# ARM_Example register map
Vendor: Infineon; Series: ARMCM3; File version: 1.2
CPU: CM3 r1p0, little endian, MPU, FPU, 3 interrupt priority bits
Registers are 32-bit, read-write, reset 0x0 unless marked. A register's access mark holds for its fields unless they carry their own. Offsets are from the block's base; [hi:lo] are bit positions; lines under a group give offsets from that group; {n}, {i} and the like mark numbered series.

## TIMER — Description of peripheral
Base 0x40010000
0x00 BITFIELD_REG (reset mask 0x1337F7F) — Register to test basic bitfield features
  [n+17:n+16] Field{n}Array (n=0..7) — Array of bitfields
    0=RISING (Only rising edges result in a counter increment or decrement); 1=FALLING (Only falling edges result in a counter increment or decrement); 2=BOTH (Rising and falling edges result in a counter increment or decrement)
  [15:12] BitfieldEnumerated — Bitfield with enumerated field
    0=CClk (Core Clock); {v}=GPIOA_{v-1} (GPIO A, PIN {v-1}) (v=1..8); {v}=GPIOB_{v-9} (GPIO B, PIN {v-9}) (v=9..12); 13=GPIOC_0 (GPIO C, PIN 0); 14=GPIOC_5 (GPIO C, PIN 1); 15=GPIOC_6 (GPIO C, PIN 2)
  [11:8] BitfieldRW — BitField Raw Read Write
  [7:6] BitfieldW wo — Bitfield Raw Write Only
  [5:3] BitfieldR ro — Raw Bitfield Read Only
  [2] BoolRW — Boolean bitfield Read Write
  [1] BoolW wo — Boolean Bitfield Write Only
  [0] BoolR ro — Boolean Bitfield Read Only
0x00 BITFIELD_REG (alt_group view) — Another defintion register using alternate group
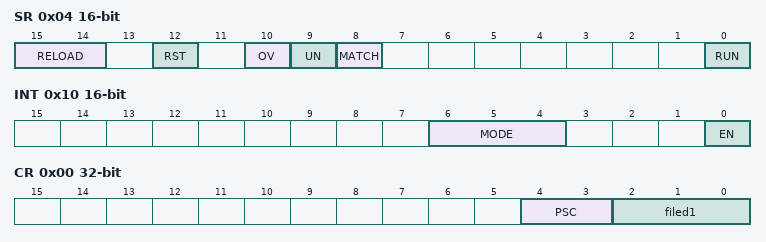
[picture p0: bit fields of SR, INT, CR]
0x04 SR 16-bit ro — Status Register
  [15:14] RELOAD — Shows the currently active RELOAD Register
    {v}=Reload Register number {v} is active (v=0..3)
  [12] RST — Shows if Timer is in RESET state
    0=Ready (Timer is not in RESET state and can operate); 1=In_Reset (Timer is in RESET state and can not operate)
  [10] OV rw — Shows if an overflow occured. This flag is sticky
    0=No overflow occured since last clear; 1=Overflow_occured (A minimum of one overflow occured since last clear)
  [9] UN rw — Shows if an underflow occured. This flag is sticky
    0=No underflow occured since last clear; 1=Underflow (A minimum of one underflow occured since last clear)
  [8] MATCH rw — Shows if the MATCH was hit
    0=No_Match (The MATCH condition was not hit); 1=Match_Hit (The MATCH condition was hit)
  [0] RUN — Shows if Timer is running or not
    0=Stopped (Timer is not running); 1=Running (Timer is running)
0x10 INT 16-bit wo — Interrupt Register
  [6:4] MODE rw — Interrupt Mode, selects on which condition the Timer should generate an Interrupt
    0=Match (Timer generates an Interrupt when the MATCH condition is hit); 1=Underflow (Timer generates an Interrupt when it underflows); 2=Overflow (Timer generates an Interrupt when it overflows)
  [0] EN rw — Interrupt Enable
    0=Disabled (Timer does not generate Interrupts); 1=Enable (Timer triggers the TIMERn Interrupt)
0x20 NOBITFIELD_REG — The Counter Register reflects the actual Value of the Timer/Counter
0x24 MATCH rw-once — The Match Register stores the compare Value for the MATCH condition
0x28 PRESCALE_RD ro — The Prescale Register stores the Value for the prescaler. The cont event gets divided by this value
0x28 PRESCALE_WR wo — The Prescale Register stores the Value for the prescaler. The cont event gets divided by this value
{0x50+4i} ARRAYREG[{i}] (i=0..3) — Array of register
0x100 Cluster1 group — Test Cluster
  0x00 CR
    [4:3] PSC, [2:0] filed1
  0x100 Cluster1 group — A cluster inside another cluster
    0x00 NestedReg reset 0x12345
{0x200+0x100*i} ClusterDim[{i}] (i=0..3) group — Test Cluster array
  0x00 CR reset 0x1000
    [4:3] PSC, [2:0] filed1

## UART[{n}] — Test cluster
Base 0x50000000; array of 3, step 0x1000
{0x0+0x100*i} Reg1_[{i}] (i=0..1) — read-write reg
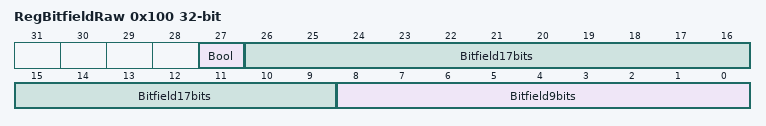
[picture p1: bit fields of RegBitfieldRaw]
0x100 RegBitfieldRaw — Register with bitfields without enumeration
  [27] Bool, [26:9] Bitfield17bits, [8:0] Bitfield9bits
0x104 Reg16bitEnum 16-bit — read write reg enum
  [16:9] Boolenum — Boolean with enum
    0=bool0; 1=bool1
  [8:0] Bitfield9bitsEnum — Check when bitfield size is not standard
0x106 Reg8bitRaw 8-bit — Read write whithout enum
0x107 Reg16bitRaw 16-bit — Read write without enum
0x109 Reg32bitRaw — Read write without enum

## FOO — Fake peripheral containing registers with names starting with non XID_Start characters that cannot be directly used as Rust identifier names.
Base 0x60000000
0x00 IN 8-bit — FOO Input Register
  [1] SELF — SELF element of FOO
    0=0_VALUE (Input is on low level.); 1=1_VALUE (Input is on high level.)
